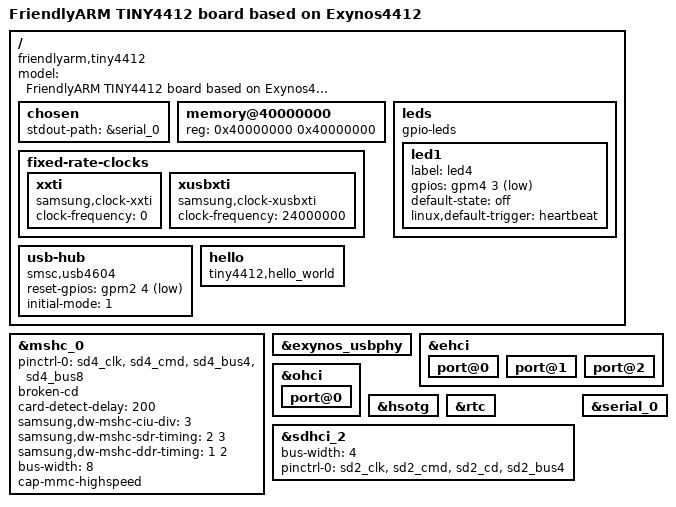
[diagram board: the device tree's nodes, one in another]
// SPDX-License-Identifier: GPL-2.0
/*
 * FriendlyARM's Exynos4412 based TINY4412 board device tree source
 *
 * Copyright (c) 2013 Alex Ling <kasimling@gmail.com>
 *
 * Device tree source file for FriendlyARM's TINY4412 board which is based on
 * Samsung's Exynos4412 SoC.
 */

/dts-v1/;
#include "exynos4412.dtsi"
#include <dt-bindings/gpio/gpio.h>

/ {
	model = "FriendlyARM TINY4412 board based on Exynos4412";
	compatible = "friendlyarm,tiny4412", "samsung,exynos4412", "samsung,exynos4";

	chosen {
		stdout-path = &serial_0;
	};

	memory@40000000 {
		device_type = "memory";
		reg = <0x40000000 0x40000000>;
	};

	leds {
		compatible = "gpio-leds";

		led1 {
			label = "led4";
			gpios = <&gpm4 3 GPIO_ACTIVE_LOW>;
			default-state = "off";
			linux,default-trigger = "heartbeat";
		};
	};

	fixed-rate-clocks {
		xxti {
			compatible = "samsung,clock-xxti";
			clock-frequency = <0>;
		};

		xusbxti {
			compatible = "samsung,clock-xusbxti";
			clock-frequency = <24000000>;
		};
	};

	usb-hub {
		compatible = "smsc,usb4604";
		reset-gpios = <&gpm2 4 GPIO_ACTIVE_LOW>;
		initial-mode = <1>;
		status = "okay";
	};

	hello {
		compatible = "tiny4412,hello_world";
		status = "okay";
	};
};

&mshc_0 {
	pinctrl-0 = <&sd4_clk &sd4_cmd &sd4_bus4 &sd4_bus8>;
	pinctrl-names = "default";
	status = "okay";

	broken-cd;
	card-detect-delay = <200>;
	samsung,dw-mshc-ciu-div = <3>;
	samsung,dw-mshc-sdr-timing = <2 3>;
	samsung,dw-mshc-ddr-timing = <1 2>;
	bus-width = <8>;
	cap-mmc-highspeed;
};

&exynos_usbphy {
	status = "okay";
};

&ehci {
	status = "okay";
	port@0 {
		status = "okay";
	};
	port@1 {
		status = "okay";
	};
	port@2 {
		status = "okay";
	};
};

&ohci {
	status = "okay";
	port@0 {
		status = "okay";
	};
};

&hsotg {
	status = "okay";
};

&rtc {
	status = "okay";
};

&sdhci_2 {
	bus-width = <4>;
	pinctrl-0 = <&sd2_clk &sd2_cmd &sd2_cd &sd2_bus4>;
	pinctrl-names = "default";
	status = "okay";
};

&serial_0 {
	status = "okay";
};

